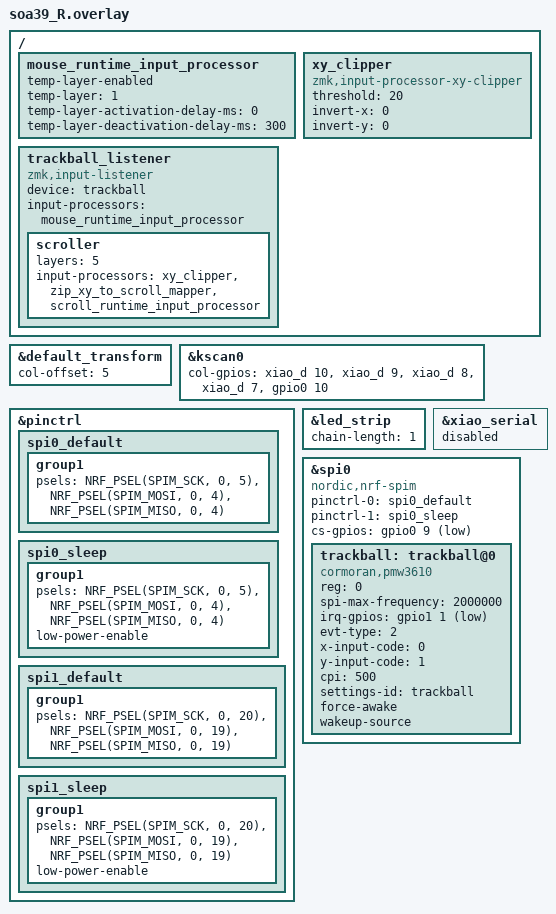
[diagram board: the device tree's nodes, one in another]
#include "soa39.dtsi"
#include <dt-bindings/zmk/input_transform.h>
#include <dt-bindings/input/input-event-codes.h>
#include <input/processors.dtsi>
#include <input/processors/runtime-input-processor.dtsi>

&default_transform {
    col-offset = <5>;
};

&kscan0 {
        col-gpios
            = <&xiao_d 10 GPIO_ACTIVE_HIGH>
            , <&xiao_d 9 GPIO_ACTIVE_HIGH>
            , <&xiao_d 8 GPIO_ACTIVE_HIGH>
            , <&xiao_d 7 GPIO_ACTIVE_HIGH>
            , <&gpio0 10 GPIO_ACTIVE_HIGH>
            ;
};

/ {
    // DYA Studio can tune pointer speed, rotation, and the 300ms auto mouse layer.
    mouse_runtime_input_processor {
        temp-layer-enabled;
        temp-layer = <1>;
        temp-layer-activation-delay-ms = <0>;
        temp-layer-deactivation-delay-ms = <300>;
    };

    xy_clipper: xy_clipper {
        compatible = "zmk,input-processor-xy-clipper";
        #input-processor-cells = <0>;
        threshold = <20>;
        invert-x = <0>;
        invert-y = <0>;
    };

    trackball_listener {
        status = "okay";
        compatible = "zmk,input-listener";
        device = <&trackball>;
        input-processors = <&mouse_runtime_input_processor>;

        scroller {
            layers = <5>;
            input-processors =
                <&xy_clipper>,
                <&zip_xy_to_scroll_mapper>,
                <&scroll_runtime_input_processor>;
        };
    };
};

&pinctrl {
    spi0_default: spi0_default {
        group1 {
            psels = <NRF_PSEL(SPIM_SCK, 0, 5)>,
                <NRF_PSEL(SPIM_MOSI, 0, 4)>,
                <NRF_PSEL(SPIM_MISO, 0, 4)>;
        };
    };

    spi0_sleep: spi0_sleep {
        group1 {
            psels = <NRF_PSEL(SPIM_SCK, 0, 5)>,
                <NRF_PSEL(SPIM_MOSI, 0, 4)>,
                <NRF_PSEL(SPIM_MISO, 0, 4)>;
            low-power-enable;
        };
    };

    spi1_default: spi1_default {
        group1 {
            psels = <NRF_PSEL(SPIM_SCK, 0, 20)>,
                <NRF_PSEL(SPIM_MOSI, 0, 19)>,
                <NRF_PSEL(SPIM_MISO, 0, 19)>;
        };
    };

    spi1_sleep: spi1_sleep {
        group1 {
            psels = <NRF_PSEL(SPIM_SCK, 0, 20)>,
                <NRF_PSEL(SPIM_MOSI, 0, 19)>,
                <NRF_PSEL(SPIM_MISO, 0, 19)>;
            low-power-enable;
        };
    };
};

// Override led_strip to set red color for right side  
&led_strip {
    status = "okay";
    chain-length = <1>;
    // Pre-set WS2812 to red color (0xFF0000) for right side identification
};

&xiao_serial { status = "disabled"; };

&spi0 {
    status = "okay";
    compatible = "nordic,nrf-spim";
    pinctrl-0 = <&spi0_default>;
    pinctrl-1 = <&spi0_sleep>;
    pinctrl-names = "default", "sleep";
    cs-gpios = <&gpio0 9 GPIO_ACTIVE_LOW>;

    trackball: trackball@0 {
        status = "okay";
        compatible = "cormoran,pmw3610";
        reg = <0>;
        spi-max-frequency = <2000000>;
        irq-gpios = <&gpio1 1 (GPIO_ACTIVE_LOW | GPIO_PULL_UP)>;
        evt-type = <2>;  // INPUT_EV_REL
        x-input-code = <0>;  // INPUT_REL_X
        y-input-code = <1>;  // INPUT_REL_Y
        cpi = <500>;
        settings-id = "trackball";
        force-awake;
        wakeup-source;
    };
};
